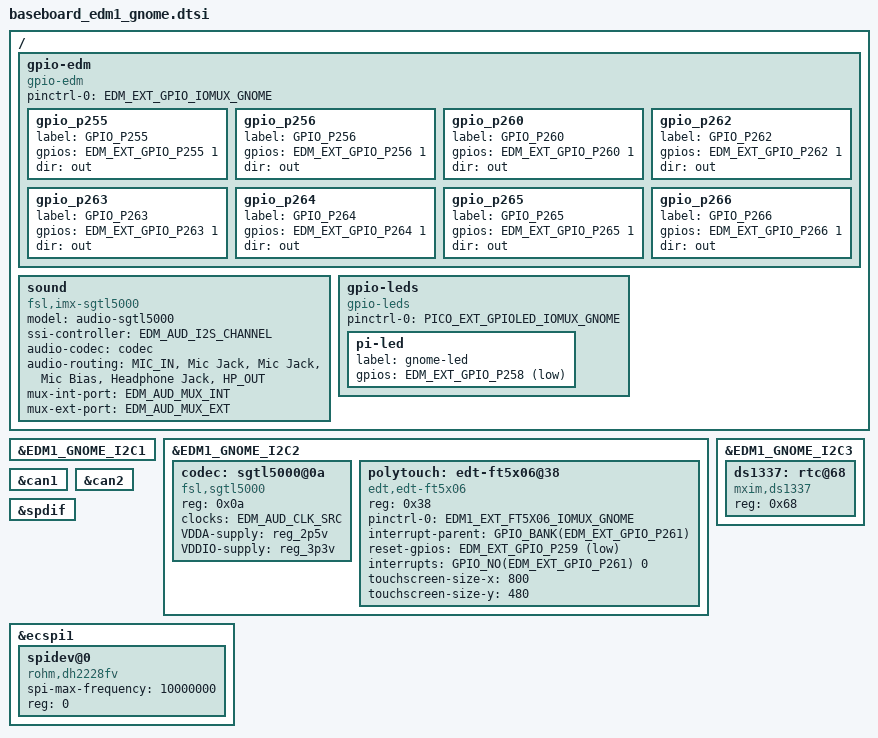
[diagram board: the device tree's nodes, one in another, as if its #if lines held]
/*
 * Copyright 2016 Technexion Ltd.
 *
 * Author: Wig Cheng <wig.cheng@technexion.com>
 *	   Richard Hu <richard.hu@technexion.com>
 *	   Tapani Utriainen <tapani@technexion.com>
 *
 * This program is free software; you can redistribute it and/or modify
 * it under the terms of the GNU General Public License version 2 as
 * published by the Free Software Foundation.
 *
 */

#include <tnmacro.h>

/ {
	gpio-edm {
		compatible = "gpio-edm";
/* custom GPIO may be from GPIO expander on CPU module */
#ifdef EDM_EXT_GPIO_IOMUX_GNOME
		pinctrl-names = "default";
		pinctrl-0 = <EDM_EXT_GPIO_IOMUX_GNOME>;
#endif
		gpio_p255 {
			label = "GPIO_P255";
			gpios = <&EDM_EXT_GPIO_P255 1>;
			dir   = "out";
		};
		gpio_p256 {
			label = "GPIO_P256";
			gpios = <&EDM_EXT_GPIO_P256 1>;
			dir   = "out";
		};
		gpio_p260 {
			label = "GPIO_P260";
			gpios = <&EDM_EXT_GPIO_P260 1>;
			dir   = "out";
		};
		gpio_p262 {
			label = "GPIO_P262";
			gpios = <&EDM_EXT_GPIO_P262 1>;
			dir   = "out";
		};
		gpio_p263 {
			label = "GPIO_P263";
			gpios = <&EDM_EXT_GPIO_P263 1>;
			dir   = "out";
		};
		gpio_p264 {
			label = "GPIO_P264";
			gpios = <&EDM_EXT_GPIO_P264 1>;
			dir   = "out";
		};
		gpio_p265 {
			label = "GPIO_P265";
			gpios = <&EDM_EXT_GPIO_P265 1>;
			dir   = "out";
		};
		gpio_p266 {
			label = "GPIO_P266";
			gpios = <&EDM_EXT_GPIO_P266 1>;
			dir   = "out";
		};
	};

	sound {
		compatible = "fsl,imx-sgtl5000",
			     "fsl,imx-audio-sgtl5000";
		model = "audio-sgtl5000";
		ssi-controller = <&EDM_AUD_I2S_CHANNEL>;
		audio-codec = <&codec>;
		audio-routing =
			"MIC_IN", "Mic Jack",
			"Mic Jack", "Mic Bias",
			"Headphone Jack", "HP_OUT";
#if defined(EDM_AUD_MUX_INT) && defined(EDM_AUD_MUX_EXT)
		mux-int-port = <EDM_AUD_MUX_INT>;
		mux-ext-port = <EDM_AUD_MUX_EXT>;
#else
	fsl,no-audmux = "true";
#endif
	};

	gpio-leds {
		compatible = "gpio-leds";
#ifdef PICO_EXT_GPIOLED_IOMUX_GNOME
			pinctrl-names = "default";
			pinctrl-0 = <PICO_EXT_GPIOLED_IOMUX_GNOME>;
#endif
		pi-led {
			label = "gnome-led";
			gpios = <&EDM_EXT_GPIO_P258 GPIO_ACTIVE_LOW>;
		};
	};
};

&EDM1_GNOME_I2C1 {
	status = "okay";
};

&EDM1_GNOME_I2C2 {
	status = "okay";

	codec: sgtl5000@0a {
		compatible = "fsl,sgtl5000";
		reg = <0x0a>;
		clocks = <&EDM_AUD_CLK_SRC>;
		VDDA-supply = <&reg_2p5v>;
		VDDIO-supply = <&reg_3p3v>;
	};

	polytouch: edt-ft5x06@38 {
		compatible = "edt,edt-ft5x06";
		reg = <0x38>;
#ifdef EDM1_EXT_FT5X06_IOMUX_GNOME
		pinctrl-names = "default";
		pinctrl-0 = <EDM1_EXT_FT5X06_IOMUX_GNOME>; /* Touch IRQ and Touch Reset */        
#endif
		interrupt-parent = <&GPIO_BANK(EDM_EXT_GPIO_P261)>; /* GPIO_P261 J1B-261 */
		reset-gpios = <&EDM_EXT_GPIO_P259 GPIO_ACTIVE_LOW>; /* GPIO_P259 J1B-259 */
		interrupts = <GPIO_NO(EDM_EXT_GPIO_P261) 0>;
		touchscreen-size-x = <800>;
		touchscreen-size-y = <480>;
	};
};

&EDM1_GNOME_I2C3 {
	status = "okay";

	ds1337: rtc@68 {
		compatible = "mxim,ds1337";
		reg = <0x68>;
	};
};

&can1 {
	status = "okay";
};

&can2 {
	status = "okay";
};

#ifdef EDM1_GNOME_ENABLE_SPDIF
&spdif {
	status = "okay";
};
#endif

&ecspi1 {
	status = "okay";

	spidev@0 {
		compatible = "rohm,dh2228fv";
		spi-max-frequency = <10000000>;
		reg = <0>;
	};
};
